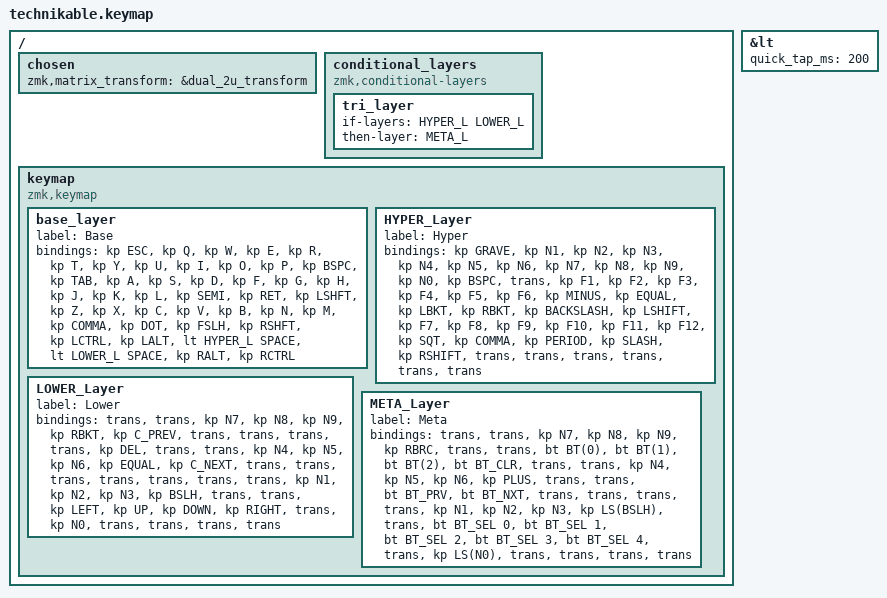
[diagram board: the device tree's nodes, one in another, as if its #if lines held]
/*
 * Copyright (c) 2022 Pete Johanson
 *
 * SPDX-License-Identifier: MIT
 */

#include <behaviors.dtsi>
#include <dt-bindings/zmk/keys.h>
#include <dt-bindings/zmk/bt.h>
#include <dt-bindings/zmk/outputs.h>

#define QWERTY_BASE 1

// #define TBLE_ORTHO   true
#define TBLE_MIT     true
// #define TBLE_DUAL_2U true

#define BAS_L 0
#define HYPER_L 1
#define LOWER_L 2
#define META_L 3

// Using layer taps on thumbs, having quick tap as well helps w/ repeating space/backspace
&lt { quick_tap_ms = <200>; };

#define BT(n) BT_SEL n

/ {
    chosen {
       zmk,matrix_transform =
#ifdef TBLE_DUAL_2U
                       &dual_2u_transform;
#elif defined(TBLE_MIT)
                       &mit_transform;
#else
                       &ortho_transform;
#endif
    };

    conditional_layers {
        compatible = "zmk,conditional-layers";
	tri_layer {
	    if-layers = <HYPER_L LOWER_L>;
	    then-layer = <META_L>;
	};
    };

    keymap {
        compatible = "zmk,keymap";


/*
 * Base layer
 */

        base_layer {
            label = "Base";
            bindings = <
#ifdef QWERTY_BASE
 &kp ESC    &kp Q      &kp W      &kp E       &kp R          &kp T          &kp Y            &kp U          &kp I       &kp O      &kp P         &kp BSPC
 &kp TAB    &kp A      &kp S      &kp D       &kp F          &kp G          &kp H            &kp J          &kp K       &kp L      &kp SEMI      &kp RET
 &kp LSHFT  &kp Z      &kp X      &kp C       &kp V          &kp B          &kp N            &kp M          &kp COMMA   &kp DOT    &kp FSLH      &kp RSHFT
#else
 &kp ESC    &kp Q      &kp W      &kp F       &kp P          &kp B          &kp J            &kp L          &kp U       &kp Y      &kp SQT     &kp BSPC
 &kp TAB    &kp A      &kp R      &kp S       &kp T          &kp G          &kp M            &kp N          &kp E       &kp I      &kp O        &kp RET
 &kp LSHFT  &kp Z      &kp X      &kp C       &kp D          &kp V          &kp K            &kp H          &kp COMMA   &kp DOT    &kp FSLH     &kp RSHFT
#endif

#ifdef TBLE_DUAL_2U
                       &kp LCTRL  &kp LALT      &lt HYPER_L SPACE                &lt LOWER_L SPACE              &kp RALT    &kp RCTRL
#elif defined(TBLE_MIT)
                           &kp LCTRL       &kp LALT     &kp LEFT_COMMAND     &kp SPACE      &mo HYPER_L     &mo LOWER_L     &mo META_L
#else
                       &kp LCTRL  &kp LALT    &mo HYPER_L         &kp SPACE      &kp SPACE        &mo LOWER_L      &kp RALT    &kp RCTRL
#endif
            >;
        };

/*
 * Hyper layer
 */

        HYPER_Layer {
            label = "Hyper";
            bindings = <
&kp GRAVE  &kp N1     &kp N2    &kp N3  &kp N4  &kp N5  &kp N6  &kp N7      &kp N8      &kp N9         &kp N0      &kp BSPC
&trans     &kp F1     &kp F2    &kp F3  &kp F4  &kp F5  &kp F6  &kp MINUS   &kp EQUAL   &kp LBKT       &kp RBKT    &kp BACKSLASH
&kp LSHIFT &kp F7     &kp F8    &kp F9  &kp F10 &kp F11 &kp F12 &kp SQT     &kp COMMA   &kp PERIOD     &kp SLASH   &kp RSHIFT
#ifdef TBLE_DUAL_2U
                      &trans     &trans              &trans                    &trans       &trans         &trans
#elif defined(TBLE_MIT)
                      &kp LCTRL       &kp LALT     &kp LEFT_COMMAND                &trans             &trans      &trans   &trans
#else
                      &trans     &trans      &trans          &trans       &trans    &trans  &trans         &trans
#endif
            >;
        };

/*
 * Lower layer
 */

        LOWER_Layer {
            label = "Lower";
            bindings = <
&trans     &trans   &kp N7     &kp N8      &kp N9    &kp RBKT    &kp C_PREV    &trans      &trans       &trans     &trans     &kp DEL
&trans     &trans   &kp N4     &kp N5      &kp N6    &kp EQUAL   &kp C_NEXT    &trans      &trans       &trans     &trans     &trans
&trans     &trans   &kp N1     &kp N2      &kp N3    &kp BSLH    &trans        &trans      &kp LEFT     &kp UP     &kp DOWN   &kp RIGHT
#ifdef TBLE_DUAL_2U
                     &trans     &kp N0              &trans                 &trans            &trans         &trans
#elif defined(TBLE_MIT)
                   &kp LCTRL       &kp LALT     &kp LEFT_COMMAND          &none           &trans       &trans      &trans
#else
                     &trans     &kp N0      &trans    &none         &none     &kp ESC        &kp DEL      &trans
#endif
            >;
        };

        META_Layer {
            label = "Meta";
            bindings = <
&trans     &trans   &kp N7     &kp N8      &kp N9   &kp RBRC     &trans  &trans         &bt BT(0)       &bt BT(1)       &bt BT(2)       &bt BT_CLR
&trans     &trans   &kp N4     &kp N5      &kp N6   &kp PLUS     &trans  &trans         &bt BT_PRV      &bt BT_NXT      &trans          &trans
&trans     &trans   &kp N1     &kp N2      &kp N3   &kp LS(BSLH) &trans  &bt BT_SEL 0   &bt BT_SEL 1    &bt BT_SEL 2    &bt BT_SEL 3    &bt BT_SEL 4
#ifdef TBLE_DUAL_2U
                      &trans     &kp LS(N0)              &trans                    &trans       &trans         &trans
#elif defined(TBLE_MIT)
                      &kp N0     &kp KP_COMMA     &kp RET                  &trans             &trans      &trans   &trans
#else
                      &trans     &kp LS(N0)      &trans          &trans       &trans    &trans  &trans         &trans
#endif
            >;
        };

    };
};
